# EFR32MG27C230F768IM40 register map
Vendor: Silicon Labs; Series: EFR32; File version: B
Registers are 32-bit, read-write, reset 0x0 unless marked. A register's access mark holds for its fields unless they carry their own. Offsets are from the block's base; [hi:lo] are bit positions; {n}, {i} and the like mark numbered series.

## SEPUF_NS_APBCFG — SEPUF_NS_APBCFG Registers
Base 0x500A0000
Same registers: SEPUF_S_APBCFG 0x400A0000
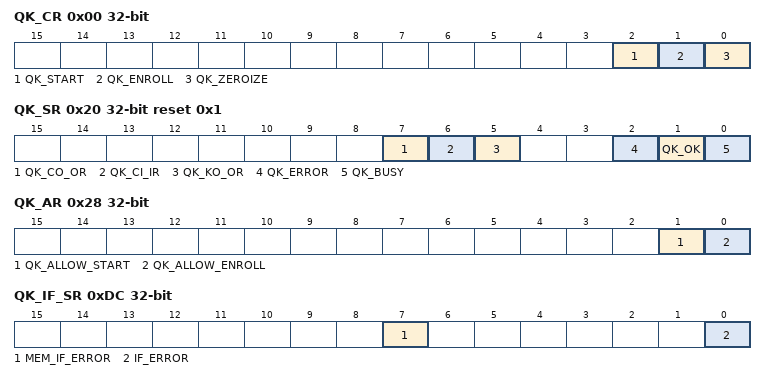
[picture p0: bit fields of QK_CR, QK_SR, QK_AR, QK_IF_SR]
0x00 QK_CR wo — Quiddikey Control register
  [2] QK_START, [1] QK_ENROLL, [0] QK_ZEROIZE
0x20 QK_SR ro reset 0x1 — Quiddikey Status register
  [7] QK_CO_OR, [6] QK_CI_IR, [5] QK_KO_OR, [2] QK_ERROR, [1] QK_OK, [0] QK_BUSY
0x28 QK_AR ro — Quiddikey Allow register
  [1] QK_ALLOW_START, [0] QK_ALLOW_ENROLL
0x44 QK_CI wo — Quiddikey Code Input register
  [0] QK_CI
0x48 QK_CO ro — Quiddikey Code Output register
  [0] QK_CO
0xDC QK_IF_SR — Quiddikey Interface Status register
  [7] MEM_IF_ERROR, [0] IF_ERROR
0xFC QK_VER ro reset 0x18910201 — Quiddikey Version register
  [31:0] QK_VERSION

## SMU_NS_CFGNS — SMU_NS_CFGNS Registers
Base 0x5400C000
Same registers: SMU_S_CFGNS 0x4400C000
0x04 NSSTATUS ro — Register for status flags.
  [0] SMUNSLOCK — SMUNS Lock Status
    0=UNLOCKED (SMUNSLOCK Unlocked); 1=LOCKED (SMUNSLOCK Locked)
0x08 NSLOCK wo — Register used to lock/unlock access to the register file.
  [23:0] SMUNSLOCKKEY — SMU Non-Secure Lock/Key
    0xACCE55=UNLOCK (Unlocks Registers)
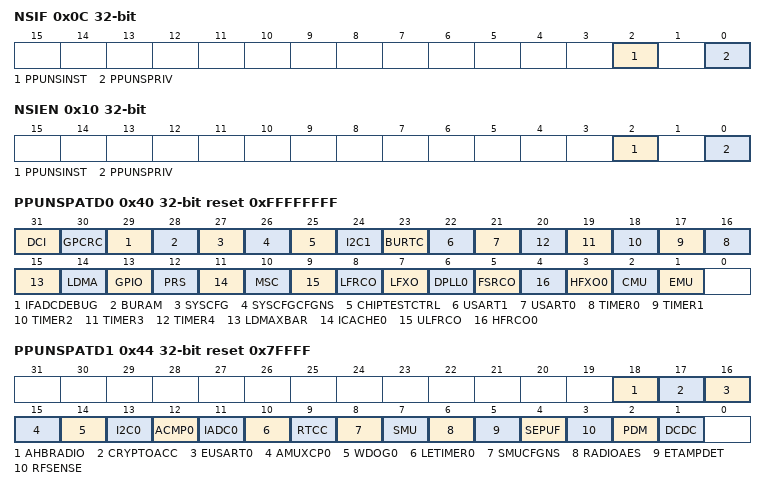
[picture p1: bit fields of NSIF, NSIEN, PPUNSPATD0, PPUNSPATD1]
0x0C NSIF — Register for interrupt status flags.
  [2] PPUNSINST — PPUNS Instruction Interrupt Flag
  [0] PPUNSPRIV — PPUNS Privilege Interrupt Flag
0x10 NSIEN — Register used for enabling/disabling interrupts.
  [2] PPUNSINST — PPUNS Instruction Interrupt Enable
  [0] PPUNSPRIV — PPUNS Privilege Interrupt Enable
0x40 PPUNSPATD0 reset 0xFFFFFFFF — Set peripheral bits to 1 to mark as privileged access only.
  [31] DCI — DCI Privileged Access
  [30] GPCRC — GPCRC Privileged Access
  [29] IFADCDEBUG — IFADCDEBUG Privileged Access
  [28] BURAM — BURAM Privileged Access
  [27] SYSCFG — SYSCFG Privileged Access
  [26] SYSCFGCFGNS — SYSCFGCFGNS Privileged Access
  [25] CHIPTESTCTRL — CHIPTESTCTRL Privileged Access
  [24] I2C1 — I2C1 Privileged Access
  [23] BURTC — BURTC Privileged Access
  [22] USART1 — USART1 Privileged Access
  [21] USART0 — USART0 Privileged Access
  [n+16] TIMER{n} (n=0..4) — TIMER{n} Privileged Access
  [15] LDMAXBAR — LDMAXBAR Privileged Access
  [14] LDMA — LDMA Privileged Access
  [13] GPIO — GPIO Privileged Access
  [12] PRS — PRS Privileged Access
  [11] ICACHE0 — ICACHE0 Privileged Access
  [10] MSC — MSC Privileged Access
  [9] ULFRCO — ULFRCO Privileged Access
  [8] LFRCO — LFRCO Privileged Access
  [7] LFXO — LFXO Privileged Access
  [6] DPLL0 — DPLL0 Privileged Access
  [5] FSRCO — FSRCO Privileged Access
  [4] HFRCO0 — HFRCO0 Privileged Access
  [3] HFXO0 — HFXO0 Privileged Access
  [2] CMU — CMU Privileged Access
  [1] EMU — EMU Privileged Access
0x44 PPUNSPATD1 reset 0x7FFFF — Set peripheral bits to 1 to mark as privileged access only.
  [18] AHBRADIO — AHBRADIO Privileged Access
  [17] CRYPTOACC — CRYPTOACC Privileged Access
  [16] EUSART0 — EUSART0 Privileged Access
  [15] AMUXCP0 — AMUXCP0 Privileged Access
  [14] WDOG0 — WDOG0 Privileged Access
  [13] I2C0 — I2C0 Privileged Access
  [12] ACMP0 — ACMP0 Privileged Access
  [11] IADC0 — IADC0 Privileged Access
  [10] LETIMER0 — LETIMER0 Privileged Access
  [9] RTCC — RTCC Privileged Access
  [8] SMUCFGNS — SMUCFGNS Privileged Access
  [7] SMU — SMU Privileged Access
  [6] RADIOAES — RADIOAES Privileged Access
  [5] ETAMPDET — ETAMPDET Privileged Access
  [4] SEPUF — SEPUF Privileged Access
  [3] RFSENSE — RFSENSE Privileged Access
  [2] PDM — PDM Privileged Access
  [1] DCDC — DCDC Privileged Access
0x140 PPUNSFS ro — Read this register to query the fault status.
  [7:0] PPUFSPERIPHID — Peripheral ID
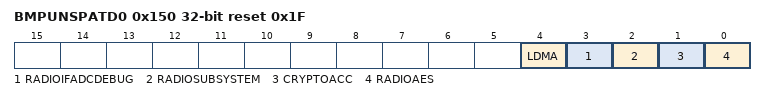
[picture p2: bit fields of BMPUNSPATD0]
0x150 BMPUNSPATD0 reset 0x1F — Write to set BMPU priveledged attributes.
  [4] LDMA — MCU LDMA privileged mode
  [3] RADIOIFADCDEBUG — RADIO IFADC debug privileged mode
  [2] RADIOSUBSYSTEM — RADIO subsystem manager privileged mode
  [1] CRYPTOACC — CRYPTOACC DMA privileged mode
  [0] RADIOAES — RADIO AES DMA privileged mode
